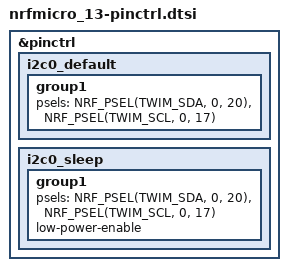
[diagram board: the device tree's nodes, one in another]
&pinctrl {
    i2c0_default: i2c0_default {
        group1 {
            psels = <NRF_PSEL(TWIM_SDA, 0, 20)>, // P0.17 as SDA
                    <NRF_PSEL(TWIM_SCL, 0, 17)>; // P0.20 as SCL
        };
    };
    i2c0_sleep: i2c0_sleep {
        group1 {
            psels = <NRF_PSEL(TWIM_SDA, 0, 20)>,
                    <NRF_PSEL(TWIM_SCL, 0, 17)>;
            low-power-enable;
        };
    };
};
